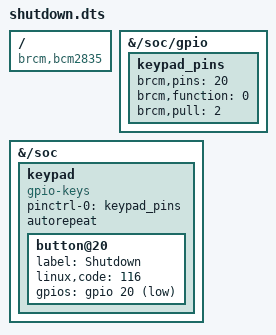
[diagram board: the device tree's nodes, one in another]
/dts-v1/;
/plugin/;
/ {
   compatible = "brcm,bcm2835", "brcm,bcm2836", "brcm,bcm2708", "brcm,bcm2709";

  fragment@0 {
        target-path = "/soc/gpio";
        __overlay__ {
            keypad_pins: keypad_pins {
                brcm,pins = <20>;
                brcm,function = <0>;
                brcm,pull = <2>;
            };
        };
    };
   
   fragment@1 {
      target-path = "/soc";
      __overlay__ {
         keypad: keypad {
            #address-cells = <1>;
            #size-cells = <1>;
            compatible = "gpio-keys";
            pinctrl-names = "default";
            pinctrl-0 = <&keypad_pins>;
            autorepeat;
            button@20 {
               label = "Shutdown";
               linux,code = <116>;
               gpios = <&gpio 20 1>;
            };
         };
      };
   };
};
